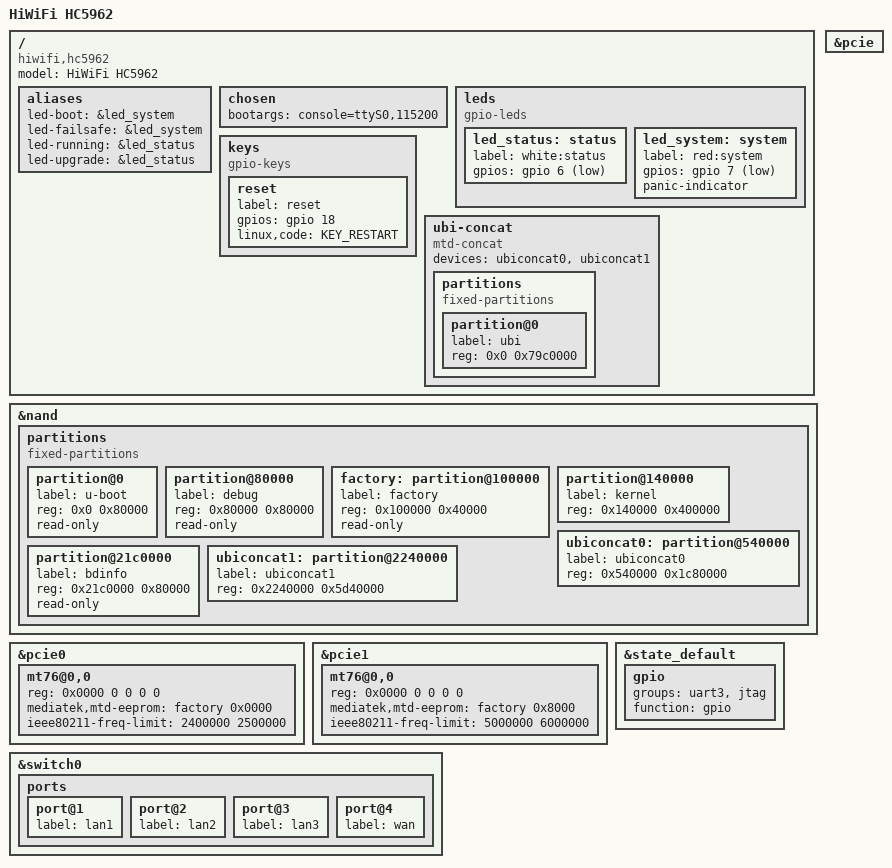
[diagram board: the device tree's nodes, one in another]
#include "mt7621.dtsi"

#include <dt-bindings/gpio/gpio.h>
#include <dt-bindings/input/input.h>

/ {
	compatible = "hiwifi,hc5962", "mediatek,mt7621-soc";
	model = "HiWiFi HC5962";

	aliases {
		led-boot = &led_system;
		led-failsafe = &led_system;
		led-running = &led_status;
		led-upgrade = &led_status;
	};

	chosen {
		bootargs = "console=ttyS0,115200";
	};

	leds {
		compatible = "gpio-leds";

		led_status: status {
			label = "white:status";
			gpios = <&gpio 6 GPIO_ACTIVE_LOW>;
		};

		led_system: system {
			label = "red:system";
			gpios = <&gpio 7 GPIO_ACTIVE_LOW>;
			panic-indicator;
		};
	};

	keys {
		compatible = "gpio-keys";

		reset {
			label = "reset";
			gpios = <&gpio 18 GPIO_ACTIVE_HIGH>;
			linux,code = <KEY_RESTART>;
		};
	};

	ubi-concat {
		compatible = "mtd-concat";
		devices = <&ubiconcat0 &ubiconcat1>;

		partitions {
			compatible = "fixed-partitions";
			#address-cells = <1>;
			#size-cells = <1>;

			partition@0 {
				label = "ubi";
				reg = <0x0 0x79c0000>;
			};
		};
	};
};

&nand {
	status = "okay";

	partitions {
		compatible = "fixed-partitions";
		#address-cells = <1>;
		#size-cells = <1>;

		partition@0 {
			label = "u-boot";
			reg = <0x0 0x80000>;
			read-only;
		};

		partition@80000 {
			label = "debug";
			reg = <0x80000 0x80000>;
			read-only;
		};

		factory: partition@100000 {
			label = "factory";
			reg = <0x100000 0x40000>;
			read-only;
		};

		partition@140000 {
			label = "kernel";
			reg = <0x140000 0x400000>;
		};

		ubiconcat0: partition@540000 {
			label = "ubiconcat0";
			reg = <0x540000 0x1c80000>;
		};

		partition@21c0000 {
			label = "bdinfo";
			reg = <0x21c0000 0x80000>;
			read-only;
		};

		ubiconcat1: partition@2240000 {
			label = "ubiconcat1";
			reg = <0x2240000 0x5d40000>;
		};
	};
};

&pcie {
	status = "okay";
};

&pcie0 {
	mt76@0,0 {
		reg = <0x0000 0 0 0 0>;
		mediatek,mtd-eeprom = <&factory 0x0000>;
		ieee80211-freq-limit = <2400000 2500000>;
	};
};

&pcie1 {
	mt76@0,0 {
		reg = <0x0000 0 0 0 0>;
		mediatek,mtd-eeprom = <&factory 0x8000>;
		ieee80211-freq-limit = <5000000 6000000>;
	};
};

&switch0 {
	ports {
		port@1 {
			status = "okay";
			label = "lan1";
		};

		port@2 {
			status = "okay";
			label = "lan2";
		};

		port@3 {
			status = "okay";
			label = "lan3";
		};

		port@4 {
			status = "okay";
			label = "wan";
		};
	};
};

&state_default {
	gpio {
		groups = "uart3", "jtag";
		function = "gpio";
	};
};
